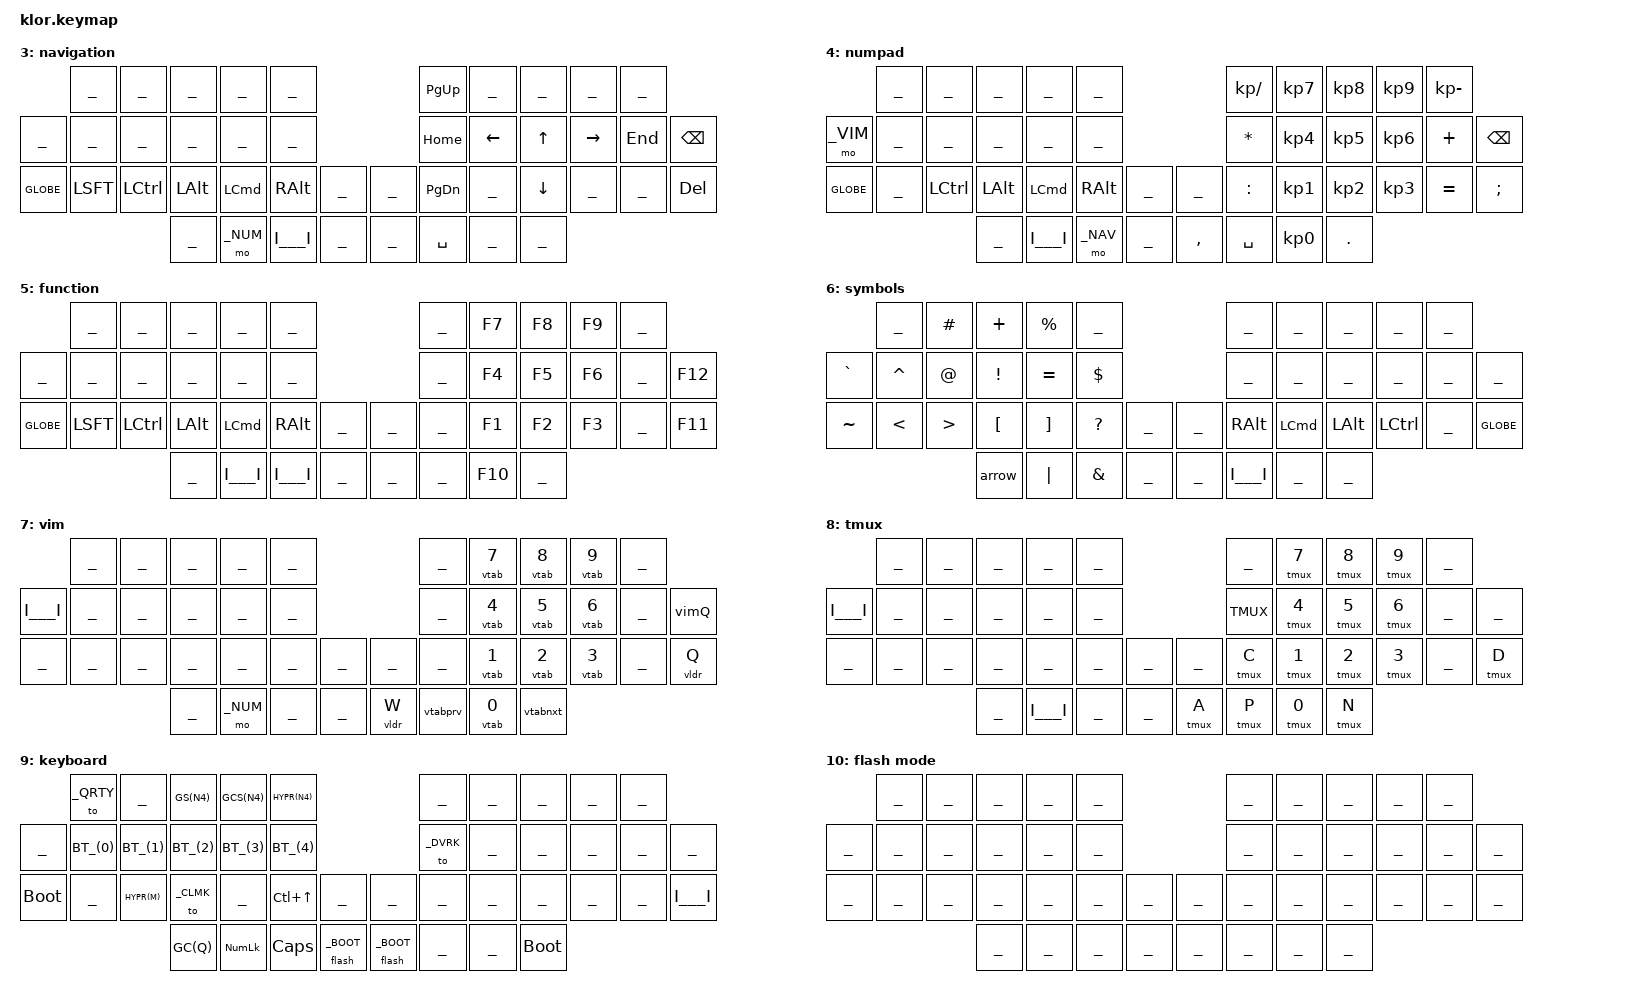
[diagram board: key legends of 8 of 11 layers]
//                               █         █    █            ▄▄▄▀▀▀▀▀▀▄▄▄        █▀▀▀▀▀▀▀▀▀▀█
//                               █        █     █          ▄▀            ▀▄      █          █
//                               █       █      █        ▄▀                ▀▄    █          █
//                               █      █       █        █                  █    █          █
//                               █     █        █       █                    █   █          █
//                               █    █         █       █                    █   █▄▄▄▄▄▄▄▄▄▄█
//                               █   █ █        █       █                    █   █      █
//                               █  █   █       █        █                  █    █       █
//                               █ █     █      █        ▀▄                ▄▀    █        █
//                               ██       █     █          ▀▄            ▄▀      █         █
//                               █         █    █▄▄▄▄▄▄▄▄    ▀▀▀▄▄▄▄▄▄▀▀▀        █          █
//
// ▄▄▄▄▄▄▄▄▄▄▄▄▄▄▄▄▄▄▄▄▄▄▄▄▄▄▄▄▄▄▄▄▄▄▄▄▄▄▄▄▄▄▄▄▄▄▄▄▄▄▄▄▄▄▄▄▄▄▄▄▄▄▄▄▄▄▄▄▄▄▄▄▄▄▄▄▄▄▄▄▄▄▄▄▄▄▄▄▄▄▄▄▄▄▄▄▄▄▄▄▄▄▄▄▄▄▄▄▄▄▄▄▄▄▄▄▄▄▄▄▄▄▄▄▄

#include <behaviors.dtsi>
#include <dt-bindings/zmk/keys.h>
#include <dt-bindings/zmk/bt.h>
#include <dt-bindings/zmk/outputs.h>
#include "common.keys"


#define _CLMK 0
#define _QRTY 1
#define _DVRK 2
#define _NAV  3
#define _NUM  4
#define _FUNC 5
#define _SYM  6
#define _VIM  7
#define _TMUX 8
#define _KBD  9
#define _BOOT 10


/ {
    conditional_layers {
        compatible = "zmk,conditional-layers";
        func_layer {
            if-layers = <_NAV _NUM>;
            then-layer = <_FUNC>;
        };
        tmux_layer {
            if-layers = <_NUM _VIM>;
            then-layer = <_TMUX>;
        };
    };

    keymap {
        compatible = "zmk,keymap";
// ▄▄▄▄▄▄▄▄▄▄▄▄▄▄▄▄▄▄▄▄▄▄▄▄▄▄▄▄▄▄▄▄▄▄▄▄▄▄▄▄▄▄▄▄▄▄▄▄▄▄▄▄▄▄▄▄▄▄▄▄▄▄▄▄▄▄▄▄▄▄▄▄▄▄▄▄▄▄▄▄▄▄▄▄▄▄▄▄▄▄▄▄▄▄▄▄▄▄▄▄▄▄▄▄▄▄▄▄▄▄▄▄▄▄▄▄▄▄▄▄▄▄▄▄▄▄▄▄▄▄▄▄▄▄▄▄▄▄▄▄▄▄


        colemak {
//                       ┌─────────────────────────────────────┐
            display-name = "Colemak"                           ;
//                       └─────────────────────────────────────┘
            bindings = <
//           ┌─────────┬─────────┬─────────┬─────────┬─────────┐                    ┌─────────┬─────────┬─────────┬─────────┬─────────┐
//           │    Q    │    W    │    F    │    P    │    B    │                    │    J    │    L    │    U    │    Y    │   ' "   │
              &kp Q     &kp W     &kp F     &kp P     &kp B                          &kp J     &kp L     &kp U     &kp Y     &kp SQT
// ┌─────────┼─────────┼─────────┼─────────┼─────────┼─────────┤                    ├─────────┼─────────┼─────────┼─────────┼─────────┼─────────┐
// │   ESC   │    A    │    R    │    S    │    T    │    G    │                    │    M    │    N    │    E    │    I    │    O    │ BACKSPC │
 &lt _VIM ESC &kp A     &kp R     &kp S     &kp T     &kp G                          &kp M     &kp N     &kp E     &kp I     &kp O     &kp BSPC
// │   vim   │         │         │         │         │         │                    │         │         │         │         │         │         │
// ├─────────┼─────────┼─────────┼─────────┼─────────┼─────────┤╭────────╮╭────────╮├─────────┼─────────┼─────────┼─────────┼─────────┼─────────┤
// │   TAB   │    Z    │    X    │    C    │    D    │    V    ││  ▶ ||  ││  MUTE  ││    K    │    H    │   , ;   │   . :   │   / \   │  ENTER  │
     Glb TAB    Sft Z     Ctl X     Opt C     Cmd D     Alt V    &kp C_PP &kp C_MUTE   Alt K     Cmd H    OPTcomma  CTRLdot  SHFTslash &lt _KBD RET
// │  globe  │  shift  │  ctrl   │   opt   │   cmd   │   alt   ││        ││        ││   alt   │   cmd   │   opt   │  ctrl   │  shift  │  keybd  │
// └─────────┴─────────┴─────────┼─────────┼─────────┼─────────┼╰────────╯╰────────╯┼─────────┼─────────┼─────────┼─────────┴─────────┴─────────┘
//                               │    {    │    (    │ [shift] │    *    ││    -    │  SPACE  │    )    │    }    │
                            Ctl LBRC &lt _NUM LPAR &lsscw _NAV 0 Cmd STAR  Cmd MINUS &lt _SYM SPC Opt RPAR Ctl RBRC
//                               │  ctrl   │   num   │   nav   │   cmd   ││   cmd   │   sym   │   opt   │  ctrl   │
//                               └─────────┴─────────┴─────────┴─────────┘└─────────┴─────────┴─────────┴─────────┘
            >;
            sensor-bindings = <&scroll>, <&inc_dec_kp C_VOL_UP C_VOL_DN>;
        };

// ▄▄▄▄▄▄▄▄▄▄▄▄▄▄▄▄▄▄▄▄▄▄▄▄▄▄▄▄▄▄▄▄▄▄▄▄▄▄▄▄▄▄▄▄▄▄▄▄▄▄▄▄▄▄▄▄▄▄▄▄▄▄▄▄▄▄▄▄▄▄▄▄▄▄▄▄▄▄▄▄▄▄▄▄▄▄▄▄▄▄▄▄▄▄▄▄▄▄▄▄▄▄▄▄▄▄▄▄▄▄▄▄▄▄▄▄▄▄▄▄▄▄▄▄▄▄▄▄▄▄▄▄▄▄▄▄▄▄▄▄▄▄


        qwerty {
//                       ┌─────────────────────────────────────┐
            display-name = "Qwerty"                            ;
//                       └─────────────────────────────────────┘
            bindings = <
//           ┌─────────┬─────────┬─────────┬─────────┬─────────┐                    ┌─────────┬─────────┬─────────┬─────────┬─────────┐
//           │    Q    │    W    │    E    │    R    │    T    │                    │    Y    │    U    │    I    │    O    │    P    │
              &kp Q     &kp W     &kp E     &kp R     &kp T                          &kp Y     &kp U     &kp I     &kp O     &kp P
// ┌─────────┼─────────┼─────────┼─────────┼─────────┼─────────┤                    ├─────────┼─────────┼─────────┼─────────┼─────────┼─────────┐
// │   ESC   │    A    │    S    │    D    │    F    │    G    │                    │    H    │    J    │    K    │    L    │   ' "   │ BACKSPC │
 &lt _VIM ESC &kp A     &kp S     &kp D     &kp F     &kp G                          &kp H     &kp J     &kp K     &kp L     &kp SQT   &kp BSPC
// │   vim   │         │         │         │         │         │                    │         │         │         │         │         │         │
// ├─────────┼─────────┼─────────┼─────────┼─────────┼─────────┤╭────────╮╭────────╮├─────────┼─────────┼─────────┼─────────┼─────────┼─────────┤
// │   TAB   │    Z    │    X    │    C    │    V    │    B    ││  ▶ ||  ││  MUTE  ││    N    │    M    │   , ;   │   . :   │   / \   │  ENTER  │
     Glb TAB    Sft Z     Ctl X     Opt C     Cmd V     Alt B    &kp C_PP &kp C_MUTE   Alt N     Cmd M    OPTcomma  CTRLdot  SHFTslash &lt _KBD RET
// │  globe  │  shift  │  ctrl   │   opt   │   cmd   │   alt   ││        ││        ││   alt   │   cmd   │   opt   │  ctrl   │  shift  │  keybd  │
// └─────────┴─────────┴─────────┼─────────┼─────────┼─────────┼╰────────╯╰────────╯┼─────────┼─────────┼─────────┼─────────┴─────────┴─────────┘
//                               │    {    │    (    │ [shift] │    *    ││    -    │  SPACE  │    )    │    }    │
                            Ctl LBRC &lt _NUM LPAR &lsscw _NAV 0 Cmd STAR  Cmd MINUS &lt _SYM SPC Opt RPAR Ctl RBRC
//                               │  ctrl   │   num   │   nav   │   cmd   ││   cmd   │   sym   │   opt   │  ctrl   │
//                               └─────────┴─────────┴─────────┴─────────┘└─────────┴─────────┴─────────┴─────────┘
            >;
            sensor-bindings = <&scroll>, <&inc_dec_kp C_VOL_UP C_VOL_DN>;
        };

// ▄▄▄▄▄▄▄▄▄▄▄▄▄▄▄▄▄▄▄▄▄▄▄▄▄▄▄▄▄▄▄▄▄▄▄▄▄▄▄▄▄▄▄▄▄▄▄▄▄▄▄▄▄▄▄▄▄▄▄▄▄▄▄▄▄▄▄▄▄▄▄▄▄▄▄▄▄▄▄▄▄▄▄▄▄▄▄▄▄▄▄▄▄▄▄▄▄▄▄▄▄▄▄▄▄▄▄▄▄▄▄▄▄▄▄▄▄▄▄▄▄▄▄▄▄


        dvorak {
//                       ┌─────────────────────────────────────┐
            display-name = "Dvorak"                            ;
//                       └─────────────────────────────────────┘
            bindings = <
//           ┌─────────┬─────────┬─────────┬─────────┬─────────┐                    ┌─────────┬─────────┬─────────┬─────────┬─────────┐
//           │   ' "   │   , ;   │   . :   │    P    │    Y    │                    │    F    │    G    │    C    │    R    │    L    │
              &kp SQT   &mcs      &mdc      &kp P     &kp Y                          &kp F     &kp G     &kp C     &kp R     &kp L
// ┌─────────┼─────────┼─────────┼─────────┼─────────┼─────────┤                    ├─────────┼─────────┼─────────┼─────────┼─────────┼─────────┐
// │   ESC   │    A    │    O    │    E    │    U    │    I    │                    │    D    │    H    │    T    │    N    │    S    │ BACKSPC │
 &lt _VIM ESC &kp A     &kp O     &kp E     &kp U     &kp I                          &kp D     &kp H     &kp T     &kp N     &kp S     &kp BSPC
// │   vim   │         │         │         │         │         │                    │         │         │         │         │         │         │
// ├─────────┼─────────┼─────────┼─────────┼─────────┼─────────┤╭────────╮╭────────╮├─────────┼─────────┼─────────┼─────────┼─────────┼─────────┤
// │   TAB   │   / \   │    Q    │    J    │    K    │    X    ││  ▶ ||  ││  MUTE  ││    B    │    M    │    W    │    V    │    Z    │  ENTER  │
     Glb TAB  SHFTslash   Ctl Q     Opt J     Cmd K     Alt X    &kp C_PP &kp C_MUTE   Alt B     Cmd M     Opt W     Ctl V     Sft Z   &lt _KBD RET
// │  globe  │  shift  │  ctrl   │   opt   │   cmd   │   alt   ││        ││        ││   alt   │   cmd   │   opt   │  ctrl   │  shift  │  keybd  │
// └─────────┴─────────┴─────────┼─────────┼─────────┼─────────┼╰────────╯╰────────╯┼─────────┼─────────┼─────────┼─────────┴─────────┴─────────┘
//                               │    {    │    (    │ [shift] │    *    ││    -    │  SPACE  │    )    │    }    │
                            Ctl LBRC &lt _NUM LPAR &lsscw _NAV 0 Cmd STAR  Cmd MINUS &lt _SYM SPC Opt RPAR Ctl RBRC
//                               │  ctrl   │   num   │   nav   │   cmd   ││   cmd   │   sym   │   opt   │  ctrl   │
//                               └─────────┴─────────┴─────────┴─────────┘└─────────┴─────────┴─────────┴─────────┘
            >;
            sensor-bindings = <&scroll>, <&inc_dec_kp C_VOL_UP C_VOL_DN>;
        };

// ▄▄▄▄▄▄▄▄▄▄▄▄▄▄▄▄▄▄▄▄▄▄▄▄▄▄▄▄▄▄▄▄▄▄▄▄▄▄▄▄▄▄▄▄▄▄▄▄▄▄▄▄▄▄▄▄▄▄▄▄▄▄▄▄▄▄▄▄▄▄▄▄▄▄▄▄▄▄▄▄▄▄▄▄▄▄▄▄▄▄▄▄▄▄▄▄▄▄▄▄▄▄▄▄▄▄▄▄▄▄▄▄▄▄▄▄▄▄▄▄▄▄▄▄▄


        navigation {
//                       ┌─────────────────────────────────────┐
            display-name = "navigation"                        ;
//                       └─────────────────────────────────────┘
            bindings = <
//           ┌─────────┬─────────┬─────────┬─────────┬─────────┐                    ┌─────────┬─────────┬─────────┬─────────┬─────────┐
//           │         │         │         │         │         │                    │  Pg Up  │         │         │         │         │
                 ___       ___       ___       ___       ___                         &kp PG_UP    ___       ___       ___       ___
// ┌─────────┼─────────┼─────────┼─────────┼─────────┼─────────┤                    ├─────────┼─────────┼─────────┼─────────┼─────────┼─────────┐
// │         │         │         │         │         │         │                    │   Home  │  Left   │   Up    │  Right  │   End   │ BACKSPC │
       ___       ___       ___       ___       ___       ___                         &kp HOME  &kp LEFT  &kp UP    &kp RIGHT &kp END   &kp BSPC
// ├─────────┼─────────┼─────────┼─────────┼─────────┼─────────┤╭────────╮╭────────╮├─────────┼─────────┼─────────┼─────────┼─────────┼─────────┤
// │  globe  │  shift  │   ctrl  │   opt   │   cmd   │   alt   ││        ││        ││ Pg Down │         │  Down   │         │         │   DEL   │
    &kp GLOBE &kp LSFT  &kp LCTL  &kp LALT  &kp LCMD  &kp RALT     ___        ___    &kp PG_DN    ___    &kp DOWN     ___       ___    &kp DEL
// └─────────┴─────────┴─────────┼─────────┼─────────┼─────────┼╰────────╯╰────────╯┼─────────┼─────────┼─────────┼─────────┴─────────┴─────────┘
//                               │         │   func  │   ###   │         ││         │  SPACE  │         │         │
                                     ___    &mo _NUM    I___I      ___       ___     &kp SPC     ___       ___
//                               └─────────┴─────────┴─────────┴─────────┘└─────────┴─────────┴─────────┴─────────┘
            >;
            sensor-bindings = <&scroll>, <&inc_dec_kp LC(TAB) LS(LC(TAB))>;
       };

// ▄▄▄▄▄▄▄▄▄▄▄▄▄▄▄▄▄▄▄▄▄▄▄▄▄▄▄▄▄▄▄▄▄▄▄▄▄▄▄▄▄▄▄▄▄▄▄▄▄▄▄▄▄▄▄▄▄▄▄▄▄▄▄▄▄▄▄▄▄▄▄▄▄▄▄▄▄▄▄▄▄▄▄▄▄▄▄▄▄▄▄▄▄▄▄▄▄▄▄▄▄▄▄▄▄▄▄▄▄▄▄▄▄▄▄▄▄▄▄▄▄▄▄▄▄


        numpad {
//                       ┌─────────────────────────────────────┐
            display-name = "numpad"                            ;
//                       └─────────────────────────────────────┘
            bindings = <
//           ┌─────────┬─────────┬─────────┬─────────┬─────────┐                    ┌─────────┬─────────┬─────────┬─────────┬─────────┐
//           │         │         │         │         │         │                    │    /    │    7    │    8    │    9    │    -    │
                 ___       ___       ___       ___       ___                      &kp KP_SLASH &kp KP_N7 &kp KP_N8 &kp KP_N9 &kp KP_MINUS
// ┌─────────┼─────────┼─────────┼─────────┼─────────┼─────────┤                    ├─────────┼─────────┼─────────┼─────────┼─────────┼─────────┐
// │   tmux  │         │         │         │         │         │                    │    *    │    4    │    5    │    6    │    +    │ BACKSPC │
    &mo _VIM     ___       ___       ___       ___       ___                         &kp STAR  &kp KP_N4 &kp KP_N5 &kp KP_N6 &kp PLUS  &kp BSPC
// ├─────────┼─────────┼─────────┼─────────┼─────────┼─────────┤╭────────╮╭────────╮├─────────┼─────────┼─────────┼─────────┼─────────┼─────────┤
// │  globe  │         │   ctrl  │   opt   │   cmd   │   alt   ││        ││        ││    :    │    1    │    2    │    3    │    =    │    ;    │
    &kp GLOBE    ___    &kp LCTL  &kp LALT  &kp LCMD  &kp RALT     ___        ___    &kp COLON &kp KP_N1 &kp KP_N2 &kp KP_N3 &kp EQUAL &kp SEMI
// └─────────┴─────────┴─────────┼─────────┼─────────┼─────────┼╰────────╯╰────────╯┼─────────┼─────────┼─────────┼─────────┴─────────┴─────────┘
//                               │         │   ###   │   func  │         ││   ,     │  SPACE  │    0    │    .    │
                                     ___      I___I   &mo _NAV     ___     &kp COMMA &kp SPC   &kp KP_N0 &kp DOT
//                               └─────────┴─────────┴─────────┴─────────┘└─────────┴─────────┴─────────┴─────────┘
            >;
            sensor-bindings = <&scroll>, <&inc_dec_kp C_VOL_UP C_VOL_DN>;
       };

// ▄▄▄▄▄▄▄▄▄▄▄▄▄▄▄▄▄▄▄▄▄▄▄▄▄▄▄▄▄▄▄▄▄▄▄▄▄▄▄▄▄▄▄▄▄▄▄▄▄▄▄▄▄▄▄▄▄▄▄▄▄▄▄▄▄▄▄▄▄▄▄▄▄▄▄▄▄▄▄▄▄▄▄▄▄▄▄▄▄▄▄▄▄▄▄▄▄▄▄▄▄▄▄▄▄▄▄▄▄▄▄▄▄▄▄▄▄▄▄▄▄▄▄▄▄


        function {
//                       ┌─────────────────────────────────────┐
            display-name = "function"                          ;
//                       └─────────────────────────────────────┘
            bindings = <
//           ┌─────────┬─────────┬─────────┬─────────┬─────────┐                    ┌─────────┬─────────┬─────────┬─────────┬─────────┐
//           │         │         │         │         │         │                    │         │   F7    │   F8    │   F9    │         │
                 ___       ___       ___       ___       ___                            ___    &kp F7    &kp F8    &kp F9       ___
// ┌─────────┼─────────┼─────────┼─────────┼─────────┼─────────┤                    ├─────────┼─────────┼─────────┼─────────┼─────────┼─────────┐
// │         │         │         │         │         │         │                    │         │   F4    │   F5    │   F6    │         │   F12   │
       ___       ___       ___       ___       ___       ___                            ___    &kp F4    &kp F5    &kp F6       ___    &kp F12
// ├─────────┼─────────┼─────────┼─────────┼─────────┼─────────┤╭────────╮╭────────╮├─────────┼─────────┼─────────┼─────────┼─────────┼─────────┤
// │  globe  │  shift  │   ctrl  │   opt   │   cmd   │   alt   ││        ││        ││         │   F1    │   F2    │   F3    │         │   F11   │
    &kp GLOBE &kp LSFT  &kp LCTL  &kp LALT  &kp LCMD  &kp RALT     ___        ___       ___    &kp F1    &kp F2    &kp F3       ___    &kp F11
// └─────────┴─────────┴─────────┼─────────┼─────────┼─────────┼╰────────╯╰────────╯┼─────────┼─────────┼─────────┼─────────┴─────────┴─────────┘
//                               │         │   ###   │   ###   │         ││         │         │   F10   │         │
                                     ___      I___I     I___I      ___        ___       ___    &kp F10      ___
//                               └─────────┴─────────┴─────────┴─────────┘└─────────┴─────────┴─────────┴─────────┘
            >;
            sensor-bindings = <&scroll>, <&inc_dec_kp C_VOL_UP C_VOL_DN>;
       };

// ▄▄▄▄▄▄▄▄▄▄▄▄▄▄▄▄▄▄▄▄▄▄▄▄▄▄▄▄▄▄▄▄▄▄▄▄▄▄▄▄▄▄▄▄▄▄▄▄▄▄▄▄▄▄▄▄▄▄▄▄▄▄▄▄▄▄▄▄▄▄▄▄▄▄▄▄▄▄▄▄▄▄▄▄▄▄▄▄▄▄▄▄▄▄▄▄▄▄▄▄▄▄▄▄▄▄▄▄▄▄▄▄▄▄▄▄▄▄▄▄▄▄▄▄▄


        symbols {
//                       ┌─────────────────────────────────────┐
            display-name = "symbols"                           ;
//                       └─────────────────────────────────────┘
            bindings = <
//           ┌─────────┬─────────┬─────────┬─────────┬─────────┐                    ┌─────────┬─────────┬─────────┬─────────┬─────────┐
//           │         │    #    │    +    │    %    │         │                    │         │         │         │         │         │
                 ___    &kp HASH  &kp PLUS  &kp PRCNT    ___                            ___       ___       ___       ___       ___
// ┌─────────┼─────────┼─────────┼─────────┼─────────┼─────────┤                    ├─────────┼─────────┼─────────┼─────────┼─────────┼─────────┐
// │    `    │    ^    │    @    │    !    │    =    │    $    │                    │         │         │         │         │         │         │
    &kp GRAVE &kp CARET &kp AT    &kp EXCL  &kp EQUAL &kp DLLR                          ___       ___       ___       ___       ___       ___
// ├─────────┼─────────┼─────────┼─────────┼─────────┼─────────┤╭────────╮╭────────╮├─────────┼─────────┼─────────┼─────────┼─────────┼─────────┤
// │    ~    │    <    │    >    │    [    │    ]    │    ?    ││        ││        ││   alt   │   cmd   │   opt   │   ctrl  │         │  globe  │
    &kp TILDE &kp LT    &kp GT    &kp LBKT  &kp RBKT  &kp QMARK    ___        ___    &kp RALT  &kp LCMD  &kp LALT  &kp LCTL     ___    &kp GLOBE
// └─────────┴─────────┴─────────┼─────────┼─────────┼─────────┼╰────────╯╰────────╯┼─────────┼─────────┼─────────┼─────────┴─────────┴─────────┘
//                               │    =>   │    |    │    &    │    _    ││         │   ###   │         │         │
                                  &arrow    &kp PIPE  &kp AMPS  &kp UNDER     ___      I___I      ___       ___
//                               └─────────┴─────────┴─────────┴─────────┘└─────────┴─────────┴─────────┴─────────┘
            >;
            sensor-bindings = <&scroll>, <&inc_dec_kp C_VOL_UP C_VOL_DN>;
        };

// ▄▄▄▄▄▄▄▄▄▄▄▄▄▄▄▄▄▄▄▄▄▄▄▄▄▄▄▄▄▄▄▄▄▄▄▄▄▄▄▄▄▄▄▄▄▄▄▄▄▄▄▄▄▄▄▄▄▄▄▄▄▄▄▄▄▄▄▄▄▄▄▄▄▄▄▄▄▄▄▄▄▄▄▄▄▄▄▄▄▄▄▄▄▄▄▄▄▄▄▄▄▄▄▄▄▄▄▄▄▄▄▄▄▄▄▄▄▄▄▄▄▄▄▄▄


        vim {
//                       ┌─────────────────────────────────────┐
            display-name = "vim"                               ;
//                       └─────────────────────────────────────┘
            bindings = <
//           ┌─────────┬─────────┬─────────┬─────────┬─────────┐                    ┌─────────┬─────────┬─────────┬─────────┬─────────┐
//           │         │         │         │         │         │                    │         │  tab 7  │  tab 8  │  tab 9  │         │
                 ___       ___       ___       ___       ___                            ___    &vtab N7  &vtab N8  &vtab N9     ___
// ┌─────────┼─────────┼─────────┼─────────┼─────────┼─────────┤                    ├─────────┼─────────┼─────────┼─────────┼─────────┼─────────┐
// │   ###   │         │         │         │         │         │                    │         │  tab 4  │  tab 5  │  tab 6  │         │   QUIT  │
      I___I      ___       ___       ___       ___       ___                            ___    &vtab N4  &vtab N5  &vtab N6     ___    &vimQ
// ├─────────┼─────────┼─────────┼─────────┼─────────┼─────────┤╭────────╮╭────────╮├─────────┼─────────┼─────────┼─────────┼─────────┼─────────┤
// │         │         │         │         │         │         ││        ││        ││         │  tab 1  │  tab 2  │  tab 3  │         │   exit  │
       ___       ___       ___       ___       ___       ___       ___        ___       ___    &vtab N1  &vtab N2  &vtab N3     ___    &vldr Q
// └─────────┴─────────┴─────────┼─────────┼─────────┼─────────┼╰────────╯╰────────╯┼─────────┼─────────┼─────────┼─────────┴─────────┴─────────┘
//                               │         │   tmux  │         │         ││   save  │ prevtab │  tab 10 │ nexttab │
                                     ___    &mo _NUM     ___       ___     &vldr W   &vtabprv  &vtab N0  &vtabnxt
//                               └─────────┴─────────┴─────────┴─────────┘└─────────┴─────────┴─────────┴─────────┘
            >;
            sensor-bindings = <&scroll>, <&vim_tabs>;
        };

// ▄▄▄▄▄▄▄▄▄▄▄▄▄▄▄▄▄▄▄▄▄▄▄▄▄▄▄▄▄▄▄▄▄▄▄▄▄▄▄▄▄▄▄▄▄▄▄▄▄▄▄▄▄▄▄▄▄▄▄▄▄▄▄▄▄▄▄▄▄▄▄▄▄▄▄▄▄▄▄▄▄▄▄▄▄▄▄▄▄▄▄▄▄▄▄▄▄▄▄▄▄▄▄▄▄▄▄▄▄▄▄▄▄▄▄▄▄▄▄▄▄▄▄▄▄


        tmux {
//                       ┌─────────────────────────────────────┐
            display-name = "tmux"                              ;
//                       └─────────────────────────────────────┘
            bindings = <
//           ┌─────────┬─────────┬─────────┬─────────┬─────────┐                    ┌─────────┬─────────┬─────────┬─────────┬─────────┐
//           │         │         │         │         │         │                    │         │  tab 7  │  tab 8  │  tab 9  │         │
                 ___       ___       ___       ___       ___                            ___    &tmux N7  &tmux N8  &tmux N9     ___
// ┌─────────┼─────────┼─────────┼─────────┼─────────┼─────────┤                    ├─────────┼─────────┼─────────┼─────────┼─────────┼─────────┐
// │   ###   │         │         │         │         │         │                    │ tmuxldr │  tab 4  │  tab 5  │  tab 6  │         │         │
      I___I      ___       ___       ___       ___       ___                         &kp TMUX  &tmux N4  &tmux N5  &tmux N6     ___       ___
// ├─────────┼─────────┼─────────┼─────────┼─────────┼─────────┤╭────────╮╭────────╮├─────────┼─────────┼─────────┼─────────┼─────────┼─────────┤
// │         │         │         │         │         │         ││        ││        ││   new   │  tab 1  │  tab 2  │  tab 3  │         │  close  │
       ___       ___       ___       ___       ___       ___       ___        ___    &tmux C   &tmux N1  &tmux N2  &tmux N3     ___    &tmux D
// └─────────┴─────────┴─────────┼─────────┼─────────┼─────────┼╰────────╯╰────────╯┼─────────┼─────────┼─────────┼─────────┴─────────┴─────────┘
//                               │         │   ###   │         │         ││   name  │ prevtab │  tab 10 │ nexttab │
                                     ___      I___I      ___       ___     &tmux A   &tmux P   &tmux N0  &tmux N
//                               └─────────┴─────────┴─────────┴─────────┘└─────────┴─────────┴─────────┴─────────┘
            >;
            sensor-bindings = <&scroll>, <&tmux_tabs>;
        };

// ▄▄▄▄▄▄▄▄▄▄▄▄▄▄▄▄▄▄▄▄▄▄▄▄▄▄▄▄▄▄▄▄▄▄▄▄▄▄▄▄▄▄▄▄▄▄▄▄▄▄▄▄▄▄▄▄▄▄▄▄▄▄▄▄▄▄▄▄▄▄▄▄▄▄▄▄▄▄▄▄▄▄▄▄▄▄▄▄▄▄▄▄▄▄▄▄▄▄▄▄▄▄▄▄▄▄▄▄▄▄▄▄▄▄▄▄▄▄▄▄▄▄▄▄▄


        keyboard {
//                       ┌─────────────────────────────────────┐
            display-name = "keyboard"                          ;
//                       └─────────────────────────────────────┘
            bindings = <
//           ┌─────────┬─────────┬─────────┬─────────┬─────────┐                    ┌─────────┬─────────┬─────────┬─────────┬─────────┐
//           │ Qwerty  │         │ scrn fl │ scrn cp │ launch  │                    │         │         │         │         │         │
              &to _QRTY    ___      GS(N4)   GCS(N4)   HYPR(N4)                         ___       ___       ___       ___       ___
// ┌─────────┼─────────┼─────────┼─────────┼─────────┼─────────┤                    ├─────────┼─────────┼─────────┼─────────┼─────────┼─────────┐
// │         │   bt1   │   bt2   │   bt3   │   bt4   │   bt5   │                    │ Dvorak  │         │         │         │         │         │
       ___    BT_(0)    BT_(1)    BT_(2)    BT_(3)    BT_(4)                         &to _DVRK    ___       ___       ___       ___       ___
// ├─────────┼─────────┼─────────┼─────────┼─────────┼─────────┤╭────────╮╭────────╮├─────────┼─────────┼─────────┼─────────┼─────────┼─────────┤
// │  flash  │         │ micmute │ Colemak │         │ mission ││        ││        ││         │         │         │         │         │   ###   │
   &bootloader   ___     HYPR(M)  &to _CLMK    ___   &kp LC(UP)    ___        ___       ___       ___       ___       ___       ___      I___I
// └─────────┴─────────┴─────────┼─────────┼─────────┼─────────┼╰────────╯╰────────╯┼─────────┼─────────┼─────────┼─────────┴─────────┴─────────┘
//                               │ scrn lk │ num lk  │ caps lk │ dongle  ││ dongle  │         │         │  flash  │
                                   GC(Q)  &kp KP_NUM &kp CAPS &flash _BOOT &flash _BOOT ___       ___   &bootloader
//                               └─────────┴─────────┴─────────┴─────────┘└─────────┴─────────┴─────────┴─────────┘
            >;
            sensor-bindings = <&inc_dec_kp C_BRI_UP C_BRI_DN>, <&inc_dec_kp C_VOL_UP C_VOL_DN>;
        };

// ▄▄▄▄▄▄▄▄▄▄▄▄▄▄▄▄▄▄▄▄▄▄▄▄▄▄▄▄▄▄▄▄▄▄▄▄▄▄▄▄▄▄▄▄▄▄▄▄▄▄▄▄▄▄▄▄▄▄▄▄▄▄▄▄▄▄▄▄▄▄▄▄▄▄▄▄▄▄▄▄▄▄▄▄▄▄▄▄▄▄▄▄▄▄▄▄▄▄▄▄▄▄▄▄▄▄▄▄▄▄▄▄▄▄▄▄▄▄▄▄▄▄▄▄▄


        flash_mode {
//                       ┌─────────────────────────────────────┐
            display-name = "flash mode"                        ;
//                       └─────────────────────────────────────┘
            bindings = <
//           ┌─────────┬─────────┬─────────┬─────────┬─────────┐                    ┌─────────┬─────────┬─────────┬─────────┬─────────┐
//           │         │         │         │         │         │                    │         │         │         │         │         │
                 ___       ___       ___       ___       ___                            ___       ___       ___       ___       ___
// ┌─────────┼─────────┼─────────┼─────────┼─────────┼─────────┤                    ├─────────┼─────────┼─────────┼─────────┼─────────┼─────────┐
// │         │         │         │         │         │         │                    │         │         │         │         │         │         │
       ___       ___       ___       ___       ___       ___                            ___       ___       ___       ___       ___       ___
// ├─────────┼─────────┼─────────┼─────────┼─────────┼─────────┤╭────────╮╭────────╮├─────────┼─────────┼─────────┼─────────┼─────────┼─────────┤
// │         │         │         │         │         │         ││        ││        ││         │         │         │         │         │         │
       ___       ___       ___       ___       ___       ___       ___        ___       ___       ___       ___       ___       ___       ___
// └─────────┴─────────┴─────────┼─────────┼─────────┼─────────┼╰────────╯╰────────╯┼─────────┼─────────┼─────────┼─────────┴─────────┴─────────┘
//                               │         │         │         │         ││         │         │         │         │
                                     ___       ___       ___       ___        ___       ___       ___       ___
//                               └─────────┴─────────┴─────────┴─────────┘└─────────┴─────────┴─────────┴─────────┘
            >;
            sensor-bindings = <&scroll>, <&inc_dec_kp C_VOL_UP C_VOL_DN>;
        };
    };
};

// vim: expandtab softtabstop=4 shiftwidth=4 filetype=devicetree
